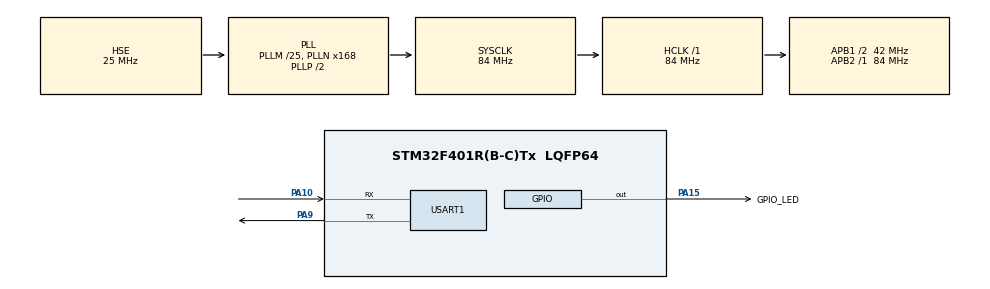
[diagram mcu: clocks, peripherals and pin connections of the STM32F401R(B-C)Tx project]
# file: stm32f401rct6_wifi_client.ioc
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Mcu.Family=STM32F4
Mcu.Name=STM32F401R(B-C)Tx
Mcu.Package=LQFP64
NVIC.PriorityGroup=NVIC_PRIORITYGROUP_4
NVIC.USART1_IRQn=true\:0\:0\:false\:false\:true\:true\:true\:true
PA10.Mode=Asynchronous
PA10.Signal=USART1_RX
PA13.Mode=Serial_Wire
PA13.Signal=SYS_JTMS-SWDIO
PA14.Mode=Serial_Wire
PA14.Signal=SYS_JTCK-SWCLK
PA15.GPIO_Label=GPIO_LED
PA15.Signal=GPIO_Output
PA9.Mode=Asynchronous
PA9.Signal=USART1_TX
PH0\ -\ OSC_IN.Mode=HSE-External-Oscillator
PH0\ -\ OSC_IN.Signal=RCC_OSC_IN
PH1\ -\ OSC_OUT.Mode=HSE-External-Oscillator
PH1\ -\ OSC_OUT.Signal=RCC_OSC_OUT
ProjectManager.HeapSize=0x200
ProjectManager.StackSize=0x400
ProjectManager.TargetToolchain=STM32CubeIDE
RCC.48MHZClocksFreq_Value=42000000
RCC.AHBFreq_Value=84000000
RCC.APB1CLKDivider=RCC_HCLK_DIV2
RCC.APB1Freq_Value=42000000
RCC.APB1TimFreq_Value=84000000
RCC.APB2Freq_Value=84000000
RCC.APB2TimFreq_Value=84000000
RCC.CortexFreq_Value=84000000
RCC.HCLKFreq_Value=84000000
RCC.HSE_VALUE=25000000
RCC.HSI_VALUE=16000000
RCC.LSE_VALUE=32768
RCC.PLLM=25
RCC.PLLN=168
RCC.PLLSourceVirtual=RCC_PLLSOURCE_HSE
RCC.SYSCLKFreq_VALUE=84000000
RCC.SYSCLKSource=RCC_SYSCLKSOURCE_PLLCLK
RCC.VCOOutputFreq_Value=168000000
USART1.VirtualMode=VM_ASYNC
board=custom

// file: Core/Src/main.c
/* USER CODE BEGIN Header */
/**
  ******************************************************************************
  * @file           : main.c
  * @brief          : Main program body
  ******************************************************************************
  * @attention
  *
  * Copyright (c) 2025 STMicroelectronics.
  * All rights reserved.
  *
  * This software is licensed under terms that can be found in the LICENSE file
  * in the root directory of this software component.
  * If no LICENSE file comes with this software, it is provided AS-IS.
  *
  ******************************************************************************
  */
/* USER CODE END Header */
#include "main.h"

/* USER CODE BEGIN Includes */
#include "string.h"
#include "stdio.h"
/* USER CODE END Includes */

/* USER CODE BEGIN PD */
#define WIFI_SSID ""
#define WIFI_PSWD ""
#define STATIC_IP ""
#define GATEWAY ""
#define SUBNET ""

/* USER CODE END PD */

UART_HandleTypeDef huart1;

/* USER CODE BEGIN PV */
uint8_t rxBuffer[512] = {0};
char ATcommand[128];
/* USER CODE END PV */

void SystemClock_Config(void);
static void MX_GPIO_Init(void);
static void MX_USART1_UART_Init(void);

/* USER CODE BEGIN 0 */
/* Function to Send AT Commands */
void sendATCommand(const char *command) {
    HAL_UART_Transmit(&huart1, (uint8_t *)command, strlen(command), 1000);
    HAL_UART_Transmit(&huart1, (uint8_t *)"\r\n", 2, 100);
    HAL_UART_Receive(&huart1, rxBuffer, 512, 2000);
    printf("Response: %s\n", rxBuffer);
}

/* Initialize Wi-Fi */
void wifi_init_client() {
    sendATCommand("AT+RST");
    HAL_Delay(5000);

    sendATCommand("AT+CWMODE_CUR=1"); // Set ESP8266 to Station Mode
    sendATCommand("AT+CWDHCP=1,0"); // Disable DHCP
    sprintf(ATcommand, "AT+CIPSTA_CUR=\"%s\",\"%s\",\"%s\"", STATIC_IP, GATEWAY, SUBNET);
    sendATCommand(ATcommand);

    sprintf(ATcommand, "AT+CWJAP_CUR=\"%s\",\"%s\"", WIFI_SSID, WIFI_PSWD);
    sendATCommand(ATcommand);
    HAL_Delay(5000);
}

/* Send TCP Message */
void send_led_command(char *command) {
    sendATCommand("AT+CIPSTART=\"TCP\",\"192.168.88.200\",80");
    HAL_Delay(1000);

    sprintf(ATcommand, "AT+CIPSEND=%d", strlen(command));
    sendATCommand(ATcommand);
    HAL_Delay(500);

    sendATCommand(command);
    HAL_Delay(500);

    sendATCommand("AT+CIPCLOSE");
    HAL_Delay(500);
}

/* Loop to Send Data */
void client_loop() {
    while (1) {
        send_led_command("LED ON");
        HAL_Delay(5000);
        send_led_command("LED OFF");
        HAL_Delay(5000);
    }
}
/* USER CODE END 0 */

int main(void)
{

  /* MCU Configuration--------------------------------------------------------*/

  /* Reset of all peripherals, Initializes the Flash interface and the Systick. */
  HAL_Init();

  /* Configure the system clock */
  SystemClock_Config();

  /* Initialize all configured peripherals */
  MX_GPIO_Init();
  MX_USART1_UART_Init();
  /* USER CODE BEGIN 2 */
  wifi_init_client();  // Initialize Wi-Fi
  client_loop();  // Send LED Commands
  /* USER CODE END 2 */

  /* Infinite loop */
  while (1)
  {

  }
}

void SystemClock_Config(void)
{
  RCC_OscInitTypeDef RCC_OscInitStruct = {0};
  RCC_ClkInitTypeDef RCC_ClkInitStruct = {0};

  /** Configure the main internal regulator output voltage
  */
  __HAL_RCC_PWR_CLK_ENABLE();
  __HAL_PWR_VOLTAGESCALING_CONFIG(PWR_REGULATOR_VOLTAGE_SCALE2);

  /** Initializes the RCC Oscillators according to the specified parameters
  * in the RCC_OscInitTypeDef structure.
  */
  RCC_OscInitStruct.OscillatorType = RCC_OSCILLATORTYPE_HSE;
  RCC_OscInitStruct.HSEState = RCC_HSE_ON;
  RCC_OscInitStruct.PLL.PLLState = RCC_PLL_ON;
  RCC_OscInitStruct.PLL.PLLSource = RCC_PLLSOURCE_HSE;
  RCC_OscInitStruct.PLL.PLLM = 25;
  RCC_OscInitStruct.PLL.PLLN = 168;
  RCC_OscInitStruct.PLL.PLLP = RCC_PLLP_DIV2;
  RCC_OscInitStruct.PLL.PLLQ = 4;
  if (HAL_RCC_OscConfig(&RCC_OscInitStruct) != HAL_OK)
  {
    Error_Handler();
  }

  /** Initializes the CPU, AHB and APB buses clocks
  */
  RCC_ClkInitStruct.ClockType = RCC_CLOCKTYPE_HCLK|RCC_CLOCKTYPE_SYSCLK
                              |RCC_CLOCKTYPE_PCLK1|RCC_CLOCKTYPE_PCLK2;
  RCC_ClkInitStruct.SYSCLKSource = RCC_SYSCLKSOURCE_PLLCLK;
  RCC_ClkInitStruct.AHBCLKDivider = RCC_SYSCLK_DIV1;
  RCC_ClkInitStruct.APB1CLKDivider = RCC_HCLK_DIV2;
  RCC_ClkInitStruct.APB2CLKDivider = RCC_HCLK_DIV1;

  if (HAL_RCC_ClockConfig(&RCC_ClkInitStruct, FLASH_LATENCY_2) != HAL_OK)
  {
    Error_Handler();
  }
}

static void MX_USART1_UART_Init(void)
{

  huart1.Instance = USART1;
  huart1.Init.BaudRate = 115200;
  huart1.Init.WordLength = UART_WORDLENGTH_8B;
  huart1.Init.StopBits = UART_STOPBITS_1;
  huart1.Init.Parity = UART_PARITY_NONE;
  huart1.Init.Mode = UART_MODE_TX_RX;
  huart1.Init.HwFlowCtl = UART_HWCONTROL_NONE;
  huart1.Init.OverSampling = UART_OVERSAMPLING_16;
  if (HAL_UART_Init(&huart1) != HAL_OK)
  {
    Error_Handler();
  }

}

static void MX_GPIO_Init(void)
{
  GPIO_InitTypeDef GPIO_InitStruct = {0};

  /* GPIO Ports Clock Enable */
  __HAL_RCC_GPIOH_CLK_ENABLE();
  __HAL_RCC_GPIOA_CLK_ENABLE();

  /*Configure GPIO pin Output Level */
  HAL_GPIO_WritePin(GPIO_LED_GPIO_Port, GPIO_LED_Pin, GPIO_PIN_RESET);

  /*Configure GPIO pin : GPIO_LED_Pin */
  GPIO_InitStruct.Pin = GPIO_LED_Pin;
  GPIO_InitStruct.Mode = GPIO_MODE_OUTPUT_PP;
  GPIO_InitStruct.Pull = GPIO_NOPULL;
  GPIO_InitStruct.Speed = GPIO_SPEED_FREQ_LOW;
  HAL_GPIO_Init(GPIO_LED_GPIO_Port, &GPIO_InitStruct);

}

void Error_Handler(void)
{
  __disable_irq();
  while (1)
  {
  }
}
